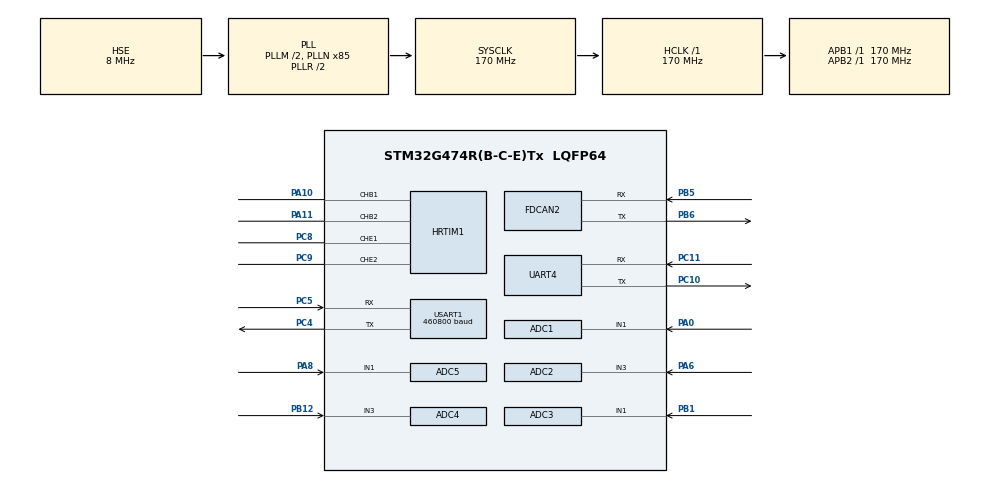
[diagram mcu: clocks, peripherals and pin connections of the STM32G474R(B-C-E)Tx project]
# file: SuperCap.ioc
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ADC1.Channel-1\#ChannelRegularConversion=ADC_CHANNEL_1
ADC1.ContinuousConvMode=DISABLE
ADC1.DMAContinuousRequests=ENABLE
ADC1.EnableInjectedConversion=DISABLE
ADC1.EnableRegularConversion=ENABLE
ADC1.ExternalTrigConv=ADC_EXTERNALTRIG_HRTIM_TRG1
ADC1.NbrOfConversionFlag=1
ADC1.OffsetNumber-1\#ChannelRegularConversion=ADC_OFFSET_NONE
ADC1.OversamplingMode=ENABLE
ADC1.Rank-1\#ChannelRegularConversion=1
ADC1.Ratio=ADC_OVERSAMPLING_RATIO_16
ADC1.RightBitShift=ADC_RIGHTBITSHIFT_4
ADC1.SamplingTime-1\#ChannelRegularConversion=ADC_SAMPLETIME_2CYCLES_5
ADC1.master=1
ADC2.Channel-0\#ChannelRegularConversion=ADC_CHANNEL_3
ADC2.ContinuousConvMode=DISABLE
ADC2.DMAContinuousRequests=ENABLE
ADC2.ExternalTrigConv=ADC_EXTERNALTRIG_HRTIM_TRG1
ADC2.NbrOfConversionFlag=1
ADC2.OffsetNumber-0\#ChannelRegularConversion=ADC_OFFSET_NONE
ADC2.OversamplingMode=ENABLE
ADC2.Rank-0\#ChannelRegularConversion=1
ADC2.Ratio=ADC_OVERSAMPLING_RATIO_16
ADC2.RightBitShift=ADC_RIGHTBITSHIFT_4
ADC2.SamplingTime-0\#ChannelRegularConversion=ADC_SAMPLETIME_24CYCLES_5
ADC3.Channel-0\#ChannelRegularConversion=ADC_CHANNEL_1
ADC3.ContinuousConvMode=DISABLE
ADC3.DMAContinuousRequests=ENABLE
ADC3.ExternalTrigConv=ADC_EXTERNALTRIG_HRTIM_TRG1
ADC3.NbrOfConversionFlag=1
ADC3.OffsetNumber-0\#ChannelRegularConversion=ADC_OFFSET_NONE
ADC3.OversamplingMode=ENABLE
ADC3.Rank-0\#ChannelRegularConversion=1
ADC3.Ratio=ADC_OVERSAMPLING_RATIO_16
ADC3.RightBitShift=ADC_RIGHTBITSHIFT_4
ADC3.SamplingTime-0\#ChannelRegularConversion=ADC_SAMPLETIME_24CYCLES_5
ADC3.master=1
ADC4.Channel-1\#ChannelRegularConversion=ADC_CHANNEL_3
ADC4.ContinuousConvMode=DISABLE
ADC4.DMAContinuousRequests=ENABLE
ADC4.ExternalTrigConv=ADC_EXTERNALTRIG_HRTIM_TRG1
ADC4.NbrOfConversion=1
ADC4.NbrOfConversionFlag=1
ADC4.OffsetNumber-1\#ChannelRegularConversion=ADC_OFFSET_NONE
ADC4.OversamplingMode=ENABLE
ADC4.Rank-1\#ChannelRegularConversion=1
ADC4.Ratio=ADC_OVERSAMPLING_RATIO_16
ADC4.RightBitShift=ADC_RIGHTBITSHIFT_4
ADC4.SamplingTime-1\#ChannelRegularConversion=ADC_SAMPLETIME_24CYCLES_5
ADC5.Channel-0\#ChannelRegularConversion=ADC_CHANNEL_1
ADC5.ContinuousConvMode=DISABLE
ADC5.DMAContinuousRequests=ENABLE
ADC5.ExternalTrigConv=ADC_EXTERNALTRIG_HRTIM_TRG1
ADC5.NbrOfConversionFlag=1
ADC5.OffsetNumber-0\#ChannelRegularConversion=ADC_OFFSET_NONE
ADC5.OversamplingMode=ENABLE
ADC5.Rank-0\#ChannelRegularConversion=1
ADC5.Ratio=ADC_OVERSAMPLING_RATIO_16
ADC5.RightBitShift=ADC_RIGHTBITSHIFT_4
ADC5.SamplingTime-0\#ChannelRegularConversion=ADC_SAMPLETIME_24CYCLES_5
Dma.ADC1.0.Direction=DMA_PERIPH_TO_MEMORY
Dma.ADC1.0.EventEnable=DISABLE
Dma.ADC1.0.Instance=DMA1_Channel1
Dma.ADC1.0.MemDataAlignment=DMA_MDATAALIGN_HALFWORD
Dma.ADC1.0.MemInc=DMA_MINC_ENABLE
Dma.ADC1.0.Mode=DMA_CIRCULAR
Dma.ADC1.0.PeriphDataAlignment=DMA_PDATAALIGN_HALFWORD
Dma.ADC1.0.PeriphInc=DMA_PINC_DISABLE
Dma.ADC1.0.Polarity=HAL_DMAMUX_REQ_GEN_RISING
Dma.ADC1.0.Priority=DMA_PRIORITY_HIGH
Dma.ADC1.0.RequestNumber=1
Dma.ADC1.0.SignalID=NONE
Dma.ADC1.0.SyncEnable=DISABLE
Dma.ADC1.0.SyncPolarity=HAL_DMAMUX_SYNC_NO_EVENT
Dma.ADC1.0.SyncRequestNumber=1
Dma.ADC1.0.SyncSignalID=NONE
Dma.ADC2.1.Direction=DMA_PERIPH_TO_MEMORY
Dma.ADC2.1.EventEnable=DISABLE
Dma.ADC2.1.Instance=DMA1_Channel2
Dma.ADC2.1.MemDataAlignment=DMA_MDATAALIGN_HALFWORD
Dma.ADC2.1.MemInc=DMA_MINC_ENABLE
Dma.ADC2.1.Mode=DMA_CIRCULAR
Dma.ADC2.1.PeriphDataAlignment=DMA_PDATAALIGN_HALFWORD
Dma.ADC2.1.PeriphInc=DMA_PINC_DISABLE
Dma.ADC2.1.Polarity=HAL_DMAMUX_REQ_GEN_RISING
Dma.ADC2.1.Priority=DMA_PRIORITY_HIGH
Dma.ADC2.1.RequestNumber=1
Dma.ADC2.1.SignalID=NONE
Dma.ADC2.1.SyncEnable=DISABLE
Dma.ADC2.1.SyncPolarity=HAL_DMAMUX_SYNC_NO_EVENT
Dma.ADC2.1.SyncRequestNumber=1
Dma.ADC2.1.SyncSignalID=NONE
Dma.ADC3.2.Direction=DMA_PERIPH_TO_MEMORY
Dma.ADC3.2.EventEnable=DISABLE
Dma.ADC3.2.Instance=DMA1_Channel3
Dma.ADC3.2.MemDataAlignment=DMA_MDATAALIGN_HALFWORD
Dma.ADC3.2.MemInc=DMA_MINC_ENABLE
Dma.ADC3.2.Mode=DMA_CIRCULAR
Dma.ADC3.2.PeriphDataAlignment=DMA_PDATAALIGN_HALFWORD
Dma.ADC3.2.PeriphInc=DMA_PINC_DISABLE
Dma.ADC3.2.Polarity=HAL_DMAMUX_REQ_GEN_RISING
Dma.ADC3.2.Priority=DMA_PRIORITY_HIGH
Dma.ADC3.2.RequestNumber=1
Dma.ADC3.2.SignalID=NONE
Dma.ADC3.2.SyncEnable=DISABLE
Dma.ADC3.2.SyncPolarity=HAL_DMAMUX_SYNC_NO_EVENT
Dma.ADC3.2.SyncRequestNumber=1
Dma.ADC3.2.SyncSignalID=NONE
Dma.ADC4.3.Direction=DMA_PERIPH_TO_MEMORY
Dma.ADC4.3.EventEnable=DISABLE
Dma.ADC4.3.Instance=DMA2_Channel1
Dma.ADC4.3.MemDataAlignment=DMA_MDATAALIGN_HALFWORD
Dma.ADC4.3.MemInc=DMA_MINC_ENABLE
Dma.ADC4.3.Mode=DMA_CIRCULAR
Dma.ADC4.3.PeriphDataAlignment=DMA_PDATAALIGN_HALFWORD
Dma.ADC4.3.PeriphInc=DMA_PINC_DISABLE
Dma.ADC4.3.Polarity=HAL_DMAMUX_REQ_GEN_RISING
Dma.ADC4.3.Priority=DMA_PRIORITY_HIGH
Dma.ADC4.3.RequestNumber=1
Dma.ADC4.3.SignalID=NONE
Dma.ADC4.3.SyncEnable=DISABLE
Dma.ADC4.3.SyncPolarity=HAL_DMAMUX_SYNC_NO_EVENT
Dma.ADC4.3.SyncRequestNumber=1
Dma.ADC4.3.SyncSignalID=NONE
Dma.ADC5.4.Direction=DMA_PERIPH_TO_MEMORY
Dma.ADC5.4.EventEnable=DISABLE
Dma.ADC5.4.Instance=DMA2_Channel2
Dma.ADC5.4.MemDataAlignment=DMA_MDATAALIGN_HALFWORD
Dma.ADC5.4.MemInc=DMA_MINC_ENABLE
Dma.ADC5.4.Mode=DMA_CIRCULAR
Dma.ADC5.4.PeriphDataAlignment=DMA_PDATAALIGN_HALFWORD
Dma.ADC5.4.PeriphInc=DMA_PINC_DISABLE
Dma.ADC5.4.Polarity=HAL_DMAMUX_REQ_GEN_RISING
Dma.ADC5.4.Priority=DMA_PRIORITY_HIGH
Dma.ADC5.4.RequestNumber=1
Dma.ADC5.4.SignalID=NONE
Dma.ADC5.4.SyncEnable=DISABLE
Dma.ADC5.4.SyncPolarity=HAL_DMAMUX_SYNC_NO_EVENT
Dma.ADC5.4.SyncRequestNumber=1
Dma.ADC5.4.SyncSignalID=NONE
Dma.Request0=ADC1
Dma.Request1=ADC2
Dma.Request2=ADC3
Dma.Request3=ADC4
Dma.Request4=ADC5
Dma.Request5=USART1_RX
Dma.Request6=USART1_TX
Dma.USART1_RX.5.Direction=DMA_PERIPH_TO_MEMORY
Dma.USART1_RX.5.EventEnable=DISABLE
Dma.USART1_RX.5.Instance=DMA1_Channel4
Dma.USART1_RX.5.MemDataAlignment=DMA_MDATAALIGN_BYTE
Dma.USART1_RX.5.MemInc=DMA_MINC_ENABLE
Dma.USART1_RX.5.Mode=DMA_NORMAL
Dma.USART1_RX.5.PeriphDataAlignment=DMA_PDATAALIGN_BYTE
Dma.USART1_RX.5.PeriphInc=DMA_PINC_DISABLE
Dma.USART1_RX.5.Polarity=HAL_DMAMUX_REQ_GEN_RISING
Dma.USART1_RX.5.Priority=DMA_PRIORITY_HIGH
Dma.USART1_RX.5.RequestNumber=1
Dma.USART1_RX.5.SignalID=NONE
Dma.USART1_RX.5.SyncEnable=DISABLE
Dma.USART1_RX.5.SyncPolarity=HAL_DMAMUX_SYNC_NO_EVENT
Dma.USART1_RX.5.SyncRequestNumber=1
Dma.USART1_RX.5.SyncSignalID=NONE
Dma.USART1_TX.6.Direction=DMA_MEMORY_TO_PERIPH
Dma.USART1_TX.6.EventEnable=DISABLE
Dma.USART1_TX.6.Instance=DMA1_Channel5
Dma.USART1_TX.6.MemDataAlignment=DMA_MDATAALIGN_BYTE
Dma.USART1_TX.6.MemInc=DMA_MINC_ENABLE
Dma.USART1_TX.6.Mode=DMA_NORMAL
Dma.USART1_TX.6.PeriphDataAlignment=DMA_PDATAALIGN_BYTE
Dma.USART1_TX.6.PeriphInc=DMA_PINC_DISABLE
Dma.USART1_TX.6.Polarity=HAL_DMAMUX_REQ_GEN_RISING
Dma.USART1_TX.6.Priority=DMA_PRIORITY_HIGH
Dma.USART1_TX.6.RequestNumber=1
Dma.USART1_TX.6.SignalID=NONE
Dma.USART1_TX.6.SyncEnable=DISABLE
Dma.USART1_TX.6.SyncPolarity=HAL_DMAMUX_SYNC_NO_EVENT
Dma.USART1_TX.6.SyncRequestNumber=1
Dma.USART1_TX.6.SyncSignalID=NONE
FDCAN2.AutoRetransmission=ENABLE
FDCAN2.CalculateBaudRateNominal=1000000
FDCAN2.CalculateTimeBitNominal=1000
FDCAN2.CalculateTimeQuantumNominal=100.0
FDCAN2.DataPrescaler=17
FDCAN2.DataTimeSeg1=5
FDCAN2.DataTimeSeg2=4
FDCAN2.ExtFiltersNbr=8
FDCAN2.NominalPrescaler=17
FDCAN2.NominalTimeSeg1=5
FDCAN2.NominalTimeSeg2=4
FDCAN2.StdFiltersNbr=28
HRTIM1.ADCTrigger1_Source1=HRTIM_ADCTRIGGEREVENT13_MASTER_PERIOD
HRTIM1.ADCTrigger_Id1=HRTIM_ADCTRIGGER_1
HRTIM1.CompareUnit1-MasterTimer=HRTIM_COMPAREUNIT_1
HRTIM1.CompareUnit2-MasterTimer=HRTIM_COMPAREUNIT_2
HRTIM1.CompareUnit3-MasterTimer=HRTIM_COMPAREUNIT_3
HRTIM1.CompareUnit3-Output_TB1TB2=__NULL
HRTIM1.CompareUnit3-Output_TE1TE2=__NULL
HRTIM1.CompareUnit4-MasterTimer=HRTIM_COMPAREUNIT_4
HRTIM1.CompareValue1-MasterTimer=13600-272
HRTIM1.CompareValue2-MasterTimer=13600+272
HRTIM1.CompareValue3-MasterTimer=13600-272
HRTIM1.CompareValue4-MasterTimer=13600+272
HRTIM1.DeadTimeInsertion-Output_TB1TB2=HRTIM_TIMDEADTIMEINSERTION_ENABLED
HRTIM1.DeadTimeInsertion-Output_TE1TE2=HRTIM_TIMDEADTIMEINSERTION_ENABLED
HRTIM1.FallingValue-Output_TB1TB2=80
HRTIM1.FallingValue-Output_TE1TE2=80
HRTIM1.NumberADCTriggerSource1=1
HRTIM1.NumberResetSource1-Output_TB1TB2=1
HRTIM1.NumberResetSource1-Output_TE1TE2=1
HRTIM1.NumberResetSource2_TB=0
HRTIM1.NumberResetSource2_TE=0
HRTIM1.NumberSetSource1-Output_TB1TB2=1
HRTIM1.NumberSetSource1-Output_TE1TE2=1
HRTIM1.NumberSetSource2_TB=0
HRTIM1.NumberSetSource2_TE=0
HRTIM1.Periode_MASTER=27200
HRTIM1.Periode_TB=27200
HRTIM1.Periode_TE=27200
HRTIM1.PreloadEnable-Output_TB1TB2=HRTIM_PRELOAD_ENABLED
HRTIM1.PreloadEnable-Output_TE1TE2=HRTIM_PRELOAD_ENABLED
HRTIM1.RepetitionUpdate-Output_TB1TB2=HRTIM_UPDATEONREPETITION_ENABLED
HRTIM1.RepetitionUpdate-Output_TE1TE2=HRTIM_UPDATEONREPETITION_ENABLED
HRTIM1.ResetOutput1_Source1-Output_TB1TB2=HRTIM_OUTPUTRESET_MASTERCMP2
HRTIM1.ResetOutput1_Source1-Output_TE1TE2=HRTIM_OUTPUTRESET_MASTERCMP4
HRTIM1.RisingValue-Output_TB1TB2=80
HRTIM1.RisingValue-Output_TE1TE2=80
HRTIM1.SetOutput1_Source1-Output_TB1TB2=HRTIM_OUTPUTSET_MASTERCMP1
HRTIM1.SetOutput1_Source1-Output_TE1TE2=HRTIM_OUTPUTSET_MASTERCMP3
HRTIM1.postscaler1=2
Mcu.Family=STM32G4
Mcu.Name=STM32G474R(B-C-E)Tx
Mcu.Package=LQFP64
NVIC.DMA1_Channel1_IRQn=true\:0\:0\:false\:false\:true\:false\:true\:true
NVIC.DMA1_Channel2_IRQn=true\:0\:0\:false\:false\:true\:false\:true\:true
NVIC.DMA1_Channel3_IRQn=true\:0\:0\:false\:false\:true\:false\:true\:true
NVIC.DMA1_Channel4_IRQn=true\:0\:0\:false\:false\:true\:false\:true\:true
NVIC.DMA1_Channel5_IRQn=true\:0\:0\:false\:false\:true\:false\:true\:true
NVIC.DMA2_Channel1_IRQn=true\:0\:0\:false\:false\:true\:false\:true\:true
NVIC.DMA2_Channel2_IRQn=true\:0\:0\:false\:false\:true\:false\:true\:true
NVIC.FDCAN2_IT0_IRQn=true\:1\:0\:true\:false\:true\:true\:true\:true
NVIC.PriorityGroup=NVIC_PRIORITYGROUP_4
NVIC.TIM2_IRQn=true\:0\:0\:false\:false\:true\:true\:true\:true
NVIC.TIM3_IRQn=true\:0\:0\:false\:false\:true\:true\:true\:true
NVIC.TIM4_IRQn=true\:0\:0\:false\:false\:true\:true\:true\:true
NVIC.USART1_IRQn=true\:0\:0\:false\:false\:true\:true\:true\:true
PA0.Mode=IN1-Single-Ended
PA0.Signal=ADC1_IN1
PA10.Mode=Output_TB1TB2
PA10.Signal=HRTIM1_CHB1
PA11.Mode=Output_TB1TB2
PA11.Signal=HRTIM1_CHB2
PA13.Mode=Serial_Wire
PA13.Signal=SYS_JTMS-SWDIO
PA14.Mode=Serial_Wire
PA14.Signal=SYS_JTCK-SWCLK
PA6.Mode=IN3-Single-Ended
PA6.Signal=ADC2_IN3
PA8.Mode=IN1-Single-Ended
PA8.Signal=ADC5_IN1
PB1.Mode=IN1-Single-Ended
PB1.Signal=ADC3_IN1
PB12.Mode=IN3-Single-Ended
PB12.Signal=ADC4_IN3
PB5.Mode=FDCAN_Activate
PB5.Signal=FDCAN2_RX
PB6.Mode=FDCAN_Activate
PB6.Signal=FDCAN2_TX
PC10.Mode=Asynchronous
PC10.Signal=UART4_TX
PC11.Mode=Asynchronous
PC11.Signal=UART4_RX
PC4.Mode=Asynchronous
PC4.Signal=USART1_TX
PC5.Mode=Asynchronous
PC5.Signal=USART1_RX
PC8.Mode=Output_TE1TE2
PC8.Signal=HRTIM1_CHE1
PC9.Mode=Output_TE1TE2
PC9.Signal=HRTIM1_CHE2
PF0-OSC_IN.Mode=HSE-External-Clock-Source
PF0-OSC_IN.Signal=RCC_OSC_IN
ProjectManager.HeapSize=0x200
ProjectManager.StackSize=0x400
ProjectManager.TargetToolchain=MDK-ARM V5.32
RCC.ADC12Freq_Value=170000000
RCC.ADC345Freq_Value=170000000
RCC.AHBFreq_Value=170000000
RCC.APB1Freq_Value=170000000
RCC.APB1TimFreq_Value=170000000
RCC.APB2Freq_Value=170000000
RCC.APB2TimFreq_Value=170000000
RCC.CortexFreq_Value=170000000
RCC.EXTERNAL_CLOCK_VALUE=12288000
RCC.HCLKFreq_Value=170000000
RCC.HSE_VALUE=8000000
RCC.HSI48_VALUE=48000000
RCC.HSI_VALUE=16000000
RCC.LSE_VALUE=32768
RCC.PLLM=RCC_PLLM_DIV2
RCC.PLLN=85
RCC.PLLSourceVirtual=RCC_PLLSOURCE_HSE
RCC.SYSCLKFreq_VALUE=170000000
RCC.SYSCLKSource=RCC_SYSCLKSOURCE_PLLCLK
RCC.USBFreq_Value=170000000
RCC.VCOOutputFreq_Value=340000000
TIM2.AutoReloadPreload=TIM_AUTORELOAD_PRELOAD_ENABLE
TIM2.PeriodNoDither=8500-1
TIM3.PeriodNoDither=850-1
TIM4.PeriodNoDither=17000-1
USART1.BaudRate=460800
USART1.VirtualMode-Asynchronous=VM_ASYNC
VP_HRTIM1_VS_hrtimMasterTimerNoOutput.Mode=MasterTimer
VP_SYS_VS_DBSignals.Mode=DisableDeadBatterySignals
VP_SYS_V_VREFBUF.Mode=ExternalMode
VP_TIM2_VS_ClockSourceINT.Mode=Internal
VP_TIM3_VS_ClockSourceINT.Mode=Internal
VP_TIM4_VS_ClockSourceINT.Mode=Internal
board=custom

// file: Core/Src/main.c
/* USER CODE BEGIN Header */
/**
  ******************************************************************************
  * @file           : main.c
  * @brief          : Main program body
  ******************************************************************************
  * @attention
  *
  * Copyright (c) 2026 STMicroelectronics.
  * All rights reserved.
  *
  * This software is licensed under terms that can be found in the LICENSE file
  * in the root directory of this software component.
  * If no LICENSE file comes with this software, it is provided AS-IS.
  *
  ******************************************************************************
  */
/* USER CODE END Header */
#include "main.h"
#include "adc.h"
#include "dma.h"
#include "fdcan.h"
#include "hrtim.h"
#include "tim.h"
#include "usart.h"
#include "gpio.h"

/* USER CODE BEGIN Includes */
#include "types.h"
#include "app_init.h"
/* USER CODE END Includes */

/* USER CODE BEGIN PV */
void SystemClock_Config(void);
/* USER CODE END PV */

void SystemClock_Config(void);

int main(void)
 {

  /* MCU Configuration--------------------------------------------------------*/

  /* Reset of all peripherals, Initializes the Flash interface and the Systick. */
  HAL_Init();

  /* Configure the system clock */
  SystemClock_Config();

  /* Initialize all configured peripherals */
  MX_GPIO_Init();
  MX_DMA_Init();
  MX_ADC1_Init();
  MX_ADC2_Init();
  MX_ADC3_Init();
  MX_ADC4_Init();
  MX_ADC5_Init();
  MX_FDCAN2_Init();
  MX_HRTIM1_Init();
  MX_UART4_Init();
  MX_USART1_UART_Init();
  MX_TIM2_Init();
  MX_TIM3_Init();
  MX_TIM4_Init();
  /* USER CODE BEGIN 2 */
	super_cap_app_init();
  /* USER CODE END 2 */

  /* Infinite loop */
   while (1)
  {

  }
}

void SystemClock_Config(void)
{
  RCC_OscInitTypeDef RCC_OscInitStruct = {0};
  RCC_ClkInitTypeDef RCC_ClkInitStruct = {0};

  /** Configure the main internal regulator output voltage
  */
  HAL_PWREx_ControlVoltageScaling(PWR_REGULATOR_VOLTAGE_SCALE1_BOOST);

  /** Initializes the RCC Oscillators according to the specified parameters
  * in the RCC_OscInitTypeDef structure.
  */
  RCC_OscInitStruct.OscillatorType = RCC_OSCILLATORTYPE_HSE;
  RCC_OscInitStruct.HSEState = RCC_HSE_BYPASS;
  RCC_OscInitStruct.PLL.PLLState = RCC_PLL_ON;
  RCC_OscInitStruct.PLL.PLLSource = RCC_PLLSOURCE_HSE;
  RCC_OscInitStruct.PLL.PLLM = RCC_PLLM_DIV2;
  RCC_OscInitStruct.PLL.PLLN = 85;
  RCC_OscInitStruct.PLL.PLLP = RCC_PLLP_DIV2;
  RCC_OscInitStruct.PLL.PLLQ = RCC_PLLQ_DIV2;
  RCC_OscInitStruct.PLL.PLLR = RCC_PLLR_DIV2;
  if (HAL_RCC_OscConfig(&RCC_OscInitStruct) != HAL_OK)
  {
    Error_Handler();
  }

  /** Initializes the CPU, AHB and APB buses clocks
  */
  RCC_ClkInitStruct.ClockType = RCC_CLOCKTYPE_HCLK|RCC_CLOCKTYPE_SYSCLK
                              |RCC_CLOCKTYPE_PCLK1|RCC_CLOCKTYPE_PCLK2;
  RCC_ClkInitStruct.SYSCLKSource = RCC_SYSCLKSOURCE_PLLCLK;
  RCC_ClkInitStruct.AHBCLKDivider = RCC_SYSCLK_DIV1;
  RCC_ClkInitStruct.APB1CLKDivider = RCC_HCLK_DIV1;
  RCC_ClkInitStruct.APB2CLKDivider = RCC_HCLK_DIV1;

  if (HAL_RCC_ClockConfig(&RCC_ClkInitStruct, FLASH_LATENCY_4) != HAL_OK)
  {
    Error_Handler();
  }
}

void Error_Handler(void)
{
  __disable_irq();
  while (1)
  {
  }
}
